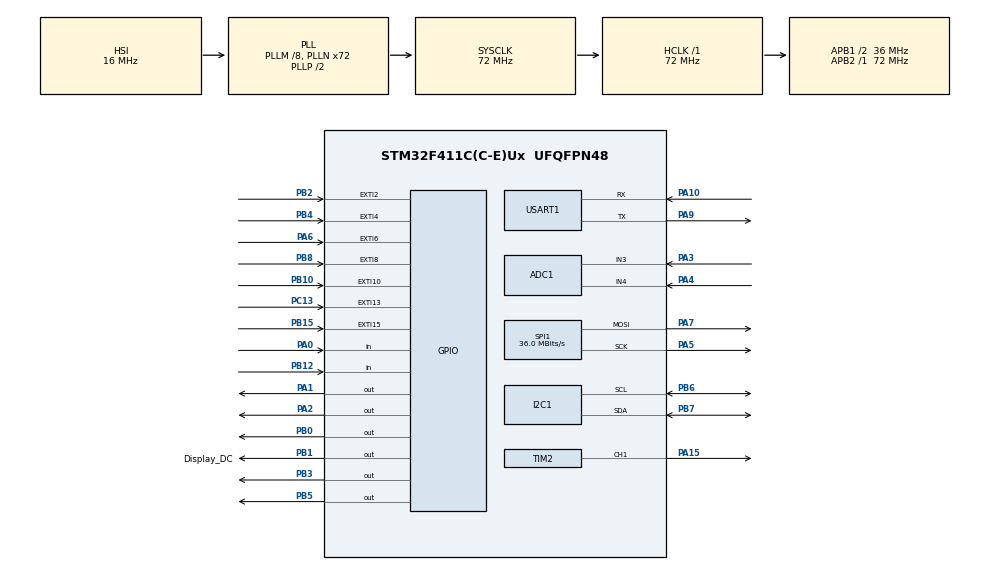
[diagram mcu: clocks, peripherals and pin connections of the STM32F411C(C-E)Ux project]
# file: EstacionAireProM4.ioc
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ADC1.Channel-0\#ChannelRegularConversion=ADC_CHANNEL_3
ADC1.ClockPrescaler=ADC_CLOCK_SYNC_PCLK_DIV4
ADC1.ContinuousConvMode=ENABLE
ADC1.NbrOfConversion=1
ADC1.NbrOfConversionFlag=1
ADC1.Rank-0\#ChannelRegularConversion=1
ADC1.SamplingTime-0\#ChannelRegularConversion=ADC_SAMPLETIME_3CYCLES
ADC1.master=1
Mcu.Family=STM32F4
Mcu.Name=STM32F411C(C-E)Ux
Mcu.Package=UFQFPN48
NVIC.EXTI15_10_IRQn=true\:0\:0\:false\:false\:true\:true\:true\:true
NVIC.EXTI2_IRQn=true\:0\:0\:false\:false\:true\:true\:true\:true
NVIC.EXTI4_IRQn=true\:0\:0\:false\:false\:true\:true\:true\:true
NVIC.EXTI9_5_IRQn=true\:0\:0\:false\:false\:true\:true\:true\:true
NVIC.PriorityGroup=NVIC_PRIORITYGROUP_4
NVIC.RCC_IRQn=true\:0\:0\:false\:false\:true\:true\:false\:true
NVIC.TIM2_IRQn=true\:0\:0\:false\:false\:true\:true\:true\:true
NVIC.TIM3_IRQn=true\:0\:0\:false\:false\:true\:true\:true\:true
PA0-WKUP.GPIO_PuPd=GPIO_PULLUP
PA0-WKUP.Signal=GPIO_Input
PA1.GPIO_ModeDefaultOutputPP=GPIO_MODE_OUTPUT_PP
PA1.Signal=GPIO_Output
PA10.Mode=Asynchronous
PA10.Signal=USART1_RX
PA13.Mode=Serial_Wire
PA13.Signal=SYS_JTMS-SWDIO
PA14.Mode=Serial_Wire
PA14.Signal=SYS_JTCK-SWCLK
PA15.GPIO_PuPd=GPIO_PULLUP
PA15.Signal=S_TIM2_CH1_ETR
PA2.Signal=GPIO_Output
PA3.Signal=ADCx_IN3
PA4.Signal=ADCx_IN4
PA5.Mode=TX_Only_Simplex_Unidirect_Master
PA5.Signal=SPI1_SCK
PA6.GPIO_ModeDefaultEXTI=GPIO_MODE_IT_RISING_FALLING
PA6.GPIO_PuPd=GPIO_PULLUP
PA6.Signal=GPXTI6
PA7.Mode=TX_Only_Simplex_Unidirect_Master
PA7.Signal=SPI1_MOSI
PA9.Mode=Asynchronous
PA9.Signal=USART1_TX
PB0.GPIO_PuPd=GPIO_PULLUP
PB0.Signal=GPIO_Output
PB1.GPIO_Label=Display_DC
PB1.GPIO_PuPd=GPIO_PULLUP
PB1.Signal=GPIO_Output
PB10.GPIO_ModeDefaultEXTI=GPIO_MODE_IT_RISING_FALLING
PB10.GPIO_PuPd=GPIO_PULLUP
PB10.Signal=GPXTI10
PB12.GPIO_PuPd=GPIO_PULLUP
PB12.Signal=GPIO_Input
PB15.GPIO_PuPd=GPIO_PULLUP
PB15.Signal=GPXTI15
PB2.GPIO_ModeDefaultEXTI=GPIO_MODE_IT_RISING_FALLING
PB2.GPIO_PuPd=GPIO_PULLUP
PB2.Signal=GPXTI2
PB3.PinState=GPIO_PIN_SET
PB3.Signal=GPIO_Output
PB4.Signal=GPXTI4
PB5.Signal=GPIO_Output
PB6.GPIO_Pu=GPIO_PULLUP
PB6.Mode=I2C
PB6.Signal=I2C1_SCL
PB7.GPIO_Pu=GPIO_PULLUP
PB7.Mode=I2C
PB7.Signal=I2C1_SDA
PB8.GPIO_PuPd=GPIO_PULLUP
PB8.Signal=GPXTI8
PC13-ANTI_TAMP.GPIO_ModeDefaultEXTI=GPIO_MODE_IT_RISING_FALLING
PC13-ANTI_TAMP.GPIO_PuPd=GPIO_PULLUP
PC13-ANTI_TAMP.Signal=GPXTI13
PH0\ -\ OSC_IN.Mode=HSE-External-Oscillator
PH0\ -\ OSC_IN.Signal=RCC_OSC_IN
PH1\ -\ OSC_OUT.Mode=HSE-External-Oscillator
PH1\ -\ OSC_OUT.Signal=RCC_OSC_OUT
ProjectManager.HeapSize=0x200
ProjectManager.StackSize=0x400
ProjectManager.TargetToolchain=STM32CubeIDE
RCC.48MHZClocksFreq_Value=36000000
RCC.AHBFreq_Value=72000000
RCC.APB1CLKDivider=RCC_HCLK_DIV2
RCC.APB1Freq_Value=36000000
RCC.APB1TimFreq_Value=72000000
RCC.APB2Freq_Value=72000000
RCC.APB2TimFreq_Value=72000000
RCC.CortexFreq_Value=72000000
RCC.HCLKFreq_Value=72000000
RCC.HSE_VALUE=25000000
RCC.HSI_VALUE=16000000
RCC.LSE_VALUE=32768
RCC.PLLM=8
RCC.PLLN=72
RCC.SYSCLKFreq_VALUE=72000000
RCC.SYSCLKSource=RCC_SYSCLKSOURCE_PLLCLK
RCC.VCOOutputFreq_Value=144000000
SH.ADCx_IN3.0=ADC1_IN3,IN3
SH.ADCx_IN4.0=ADC1_IN4,IN4
SH.S_TIM2_CH1_ETR.0=TIM2_CH1,PWM Generation1 CH1
SPI1.CalculateBaudRate=36.0 MBits/s
SPI1.Direction=SPI_DIRECTION_2LINES
SPI1.Mode=SPI_MODE_MASTER
SPI1.VirtualType=VM_MASTER
TIM2.AutoReloadPreload=TIM_AUTORELOAD_PRELOAD_ENABLE
TIM2.Channel-PWM\ Generation1\ CH1=TIM_CHANNEL_1
TIM2.Period=99
TIM2.Prescaler=71
USART1.VirtualMode=VM_ASYNC
VP_TIM2_VS_ClockSourceINT.Mode=Internal
VP_TIM3_VS_ClockSourceINT.Mode=Internal
board=custom

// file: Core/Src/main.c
/* USER CODE BEGIN Header */
/**
  ******************************************************************************
  * @file           : main.c
  * @brief          : Main program body
  ******************************************************************************
  * @attention
  *
  * Copyright (c) 2024 STMicroelectronics.
  * All rights reserved.
  *
  * This software is licensed under terms that can be found in the LICENSE file
  * in the root directory of this software component.
  * If no LICENSE file comes with this software, it is provided AS-IS.
  *
  ******************************************************************************
  */
/* USER CODE END Header */
#include "main.h"

ADC_HandleTypeDef hadc1;

I2C_HandleTypeDef hi2c1;

SPI_HandleTypeDef hspi1;

TIM_HandleTypeDef htim2;
TIM_HandleTypeDef htim3;

UART_HandleTypeDef huart1;

void SystemClock_Config(void);
static void MX_GPIO_Init(void);
static void MX_ADC1_Init(void);
static void MX_I2C1_Init(void);
static void MX_SPI1_Init(void);
static void MX_TIM2_Init(void);
static void MX_TIM3_Init(void);
static void MX_USART1_UART_Init(void);

int main(void)
{

  /* MCU Configuration--------------------------------------------------------*/

  /* Reset of all peripherals, Initializes the Flash interface and the Systick. */
  HAL_Init();

  /* Configure the system clock */
  SystemClock_Config();

  /* Initialize all configured peripherals */
  MX_GPIO_Init();
  MX_ADC1_Init();
  MX_I2C1_Init();
  MX_SPI1_Init();
  MX_TIM2_Init();
  MX_TIM3_Init();
  MX_USART1_UART_Init();
  /* USER CODE BEGIN 2 */
  HAL_TIM_Base_Start_IT(&htim3);
	IncializaSistema();
	EjecutaSistema();
  USART1_UART_Init();
	  HAL_ADC_Start(&hadc1);

  /* USER CODE END 2 */

  /* Infinite loop */
  /* USER CODE BEGIN WHILE */
  while (1)
  {
		int valor=HAL_ADC_GetValue(&hadc1);
		SerialPrintf((char*)"\r\n analogo: %d",valor);
		HAL_Delay(500);
    /* USER CODE END WHILE */

  }
}

void SystemClock_Config(void)
{
  RCC_OscInitTypeDef RCC_OscInitStruct = {0};
  RCC_ClkInitTypeDef RCC_ClkInitStruct = {0};

  /** Configure the main internal regulator output voltage
  */
  __HAL_RCC_PWR_CLK_ENABLE();
  __HAL_PWR_VOLTAGESCALING_CONFIG(PWR_REGULATOR_VOLTAGE_SCALE1);

  /** Initializes the RCC Oscillators according to the specified parameters
  * in the RCC_OscInitTypeDef structure.
  */
  RCC_OscInitStruct.OscillatorType = RCC_OSCILLATORTYPE_HSI;
  RCC_OscInitStruct.HSIState = RCC_HSI_ON;
  RCC_OscInitStruct.HSICalibrationValue = RCC_HSICALIBRATION_DEFAULT;
  RCC_OscInitStruct.PLL.PLLState = RCC_PLL_ON;
  RCC_OscInitStruct.PLL.PLLSource = RCC_PLLSOURCE_HSI;
  RCC_OscInitStruct.PLL.PLLM = 8;
  RCC_OscInitStruct.PLL.PLLN = 72;
  RCC_OscInitStruct.PLL.PLLP = RCC_PLLP_DIV2;
  RCC_OscInitStruct.PLL.PLLQ = 4;
  if (HAL_RCC_OscConfig(&RCC_OscInitStruct) != HAL_OK)
  {
    Error_Handler();
  }

  /** Initializes the CPU, AHB and APB buses clocks
  */
  RCC_ClkInitStruct.ClockType = RCC_CLOCKTYPE_HCLK|RCC_CLOCKTYPE_SYSCLK
                              |RCC_CLOCKTYPE_PCLK1|RCC_CLOCKTYPE_PCLK2;
  RCC_ClkInitStruct.SYSCLKSource = RCC_SYSCLKSOURCE_PLLCLK;
  RCC_ClkInitStruct.AHBCLKDivider = RCC_SYSCLK_DIV1;
  RCC_ClkInitStruct.APB1CLKDivider = RCC_HCLK_DIV2;
  RCC_ClkInitStruct.APB2CLKDivider = RCC_HCLK_DIV1;

  if (HAL_RCC_ClockConfig(&RCC_ClkInitStruct, FLASH_LATENCY_2) != HAL_OK)
  {
    Error_Handler();
  }
}

static void MX_ADC1_Init(void)
{

  ADC_ChannelConfTypeDef sConfig = {0};

  /** Configure the global features of the ADC (Clock, Resolution, Data Alignment and number of conversion)
  */
  hadc1.Instance = ADC1;
  hadc1.Init.ClockPrescaler = ADC_CLOCK_SYNC_PCLK_DIV4;
  hadc1.Init.Resolution = ADC_RESOLUTION_12B;
  hadc1.Init.ScanConvMode = DISABLE;
  hadc1.Init.ContinuousConvMode = ENABLE;
  hadc1.Init.DiscontinuousConvMode = DISABLE;
  hadc1.Init.ExternalTrigConvEdge = ADC_EXTERNALTRIGCONVEDGE_NONE;
  hadc1.Init.ExternalTrigConv = ADC_SOFTWARE_START;
  hadc1.Init.DataAlign = ADC_DATAALIGN_RIGHT;
  hadc1.Init.NbrOfConversion = 1;
  hadc1.Init.DMAContinuousRequests = DISABLE;
  hadc1.Init.EOCSelection = ADC_EOC_SINGLE_CONV;
  if (HAL_ADC_Init(&hadc1) != HAL_OK)
  {
    Error_Handler();
  }

  /** Configure for the selected ADC regular channel its corresponding rank in the sequencer and its sample time.
  */
  sConfig.Channel = ADC_CHANNEL_3;
  sConfig.Rank = 1;
  sConfig.SamplingTime = ADC_SAMPLETIME_3CYCLES;
  if (HAL_ADC_ConfigChannel(&hadc1, &sConfig) != HAL_OK)
  {
    Error_Handler();
  }

}

static void MX_I2C1_Init(void)
{

  hi2c1.Instance = I2C1;
  hi2c1.Init.ClockSpeed = 100000;
  hi2c1.Init.DutyCycle = I2C_DUTYCYCLE_2;
  hi2c1.Init.OwnAddress1 = 0;
  hi2c1.Init.AddressingMode = I2C_ADDRESSINGMODE_7BIT;
  hi2c1.Init.DualAddressMode = I2C_DUALADDRESS_DISABLE;
  hi2c1.Init.OwnAddress2 = 0;
  hi2c1.Init.GeneralCallMode = I2C_GENERALCALL_DISABLE;
  hi2c1.Init.NoStretchMode = I2C_NOSTRETCH_DISABLE;
  if (HAL_I2C_Init(&hi2c1) != HAL_OK)
  {
    Error_Handler();
  }

}

static void MX_SPI1_Init(void)
{

  /* SPI1 parameter configuration*/
  hspi1.Instance = SPI1;
  hspi1.Init.Mode = SPI_MODE_MASTER;
  hspi1.Init.Direction = SPI_DIRECTION_2LINES;
  hspi1.Init.DataSize = SPI_DATASIZE_8BIT;
  hspi1.Init.CLKPolarity = SPI_POLARITY_LOW;
  hspi1.Init.CLKPhase = SPI_PHASE_1EDGE;
  hspi1.Init.NSS = SPI_NSS_SOFT;
  hspi1.Init.BaudRatePrescaler = SPI_BAUDRATEPRESCALER_2;
  hspi1.Init.FirstBit = SPI_FIRSTBIT_MSB;
  hspi1.Init.TIMode = SPI_TIMODE_DISABLE;
  hspi1.Init.CRCCalculation = SPI_CRCCALCULATION_DISABLE;
  hspi1.Init.CRCPolynomial = 10;
  if (HAL_SPI_Init(&hspi1) != HAL_OK)
  {
    Error_Handler();
  }

}

static void MX_TIM2_Init(void)
{

  TIM_ClockConfigTypeDef sClockSourceConfig = {0};
  TIM_MasterConfigTypeDef sMasterConfig = {0};
  TIM_OC_InitTypeDef sConfigOC = {0};

  htim2.Instance = TIM2;
  htim2.Init.Prescaler = 71;
  htim2.Init.CounterMode = TIM_COUNTERMODE_UP;
  htim2.Init.Period = 99;
  htim2.Init.ClockDivision = TIM_CLOCKDIVISION_DIV1;
  htim2.Init.AutoReloadPreload = TIM_AUTORELOAD_PRELOAD_ENABLE;
  if (HAL_TIM_Base_Init(&htim2) != HAL_OK)
  {
    Error_Handler();
  }
  sClockSourceConfig.ClockSource = TIM_CLOCKSOURCE_INTERNAL;
  if (HAL_TIM_ConfigClockSource(&htim2, &sClockSourceConfig) != HAL_OK)
  {
    Error_Handler();
  }
  if (HAL_TIM_PWM_Init(&htim2) != HAL_OK)
  {
    Error_Handler();
  }
  sMasterConfig.MasterOutputTrigger = TIM_TRGO_RESET;
  sMasterConfig.MasterSlaveMode = TIM_MASTERSLAVEMODE_DISABLE;
  if (HAL_TIMEx_MasterConfigSynchronization(&htim2, &sMasterConfig) != HAL_OK)
  {
    Error_Handler();
  }
  sConfigOC.OCMode = TIM_OCMODE_PWM1;
  sConfigOC.Pulse = 0;
  sConfigOC.OCPolarity = TIM_OCPOLARITY_HIGH;
  sConfigOC.OCFastMode = TIM_OCFAST_DISABLE;
  if (HAL_TIM_PWM_ConfigChannel(&htim2, &sConfigOC, TIM_CHANNEL_1) != HAL_OK)
  {
    Error_Handler();
  }
  HAL_TIM_MspPostInit(&htim2);

}

static void MX_TIM3_Init(void)
{

  TIM_ClockConfigTypeDef sClockSourceConfig = {0};
  TIM_MasterConfigTypeDef sMasterConfig = {0};

  htim3.Instance = TIM3;
  htim3.Init.Prescaler = 0;
  htim3.Init.CounterMode = TIM_COUNTERMODE_UP;
  htim3.Init.Period = 65535;
  htim3.Init.ClockDivision = TIM_CLOCKDIVISION_DIV1;
  htim3.Init.AutoReloadPreload = TIM_AUTORELOAD_PRELOAD_DISABLE;
  if (HAL_TIM_Base_Init(&htim3) != HAL_OK)
  {
    Error_Handler();
  }
  sClockSourceConfig.ClockSource = TIM_CLOCKSOURCE_INTERNAL;
  if (HAL_TIM_ConfigClockSource(&htim3, &sClockSourceConfig) != HAL_OK)
  {
    Error_Handler();
  }
  sMasterConfig.MasterOutputTrigger = TIM_TRGO_RESET;
  sMasterConfig.MasterSlaveMode = TIM_MASTERSLAVEMODE_DISABLE;
  if (HAL_TIMEx_MasterConfigSynchronization(&htim3, &sMasterConfig) != HAL_OK)
  {
    Error_Handler();
  }

}

static void MX_USART1_UART_Init(void)
{

  huart1.Instance = USART1;
  huart1.Init.BaudRate = 115200;
  huart1.Init.WordLength = UART_WORDLENGTH_8B;
  huart1.Init.StopBits = UART_STOPBITS_1;
  huart1.Init.Parity = UART_PARITY_NONE;
  huart1.Init.Mode = UART_MODE_TX_RX;
  huart1.Init.HwFlowCtl = UART_HWCONTROL_NONE;
  huart1.Init.OverSampling = UART_OVERSAMPLING_16;
  if (HAL_UART_Init(&huart1) != HAL_OK)
  {
    Error_Handler();
  }

}

static void MX_GPIO_Init(void)
{
  GPIO_InitTypeDef GPIO_InitStruct = {0};

  /* GPIO Ports Clock Enable */
  __HAL_RCC_GPIOC_CLK_ENABLE();
  __HAL_RCC_GPIOH_CLK_ENABLE();
  __HAL_RCC_GPIOA_CLK_ENABLE();
  __HAL_RCC_GPIOB_CLK_ENABLE();

  /*Configure GPIO pin Output Level */
  HAL_GPIO_WritePin(GPIOA, GPIO_PIN_1|GPIO_PIN_2, GPIO_PIN_RESET);

  /*Configure GPIO pin Output Level */
  HAL_GPIO_WritePin(GPIOB, GPIO_PIN_0|Display_DC_Pin|GPIO_PIN_5, GPIO_PIN_RESET);

  /*Configure GPIO pin Output Level */
  HAL_GPIO_WritePin(GPIOB, GPIO_PIN_3, GPIO_PIN_SET);

  /*Configure GPIO pin : PC13 */
  GPIO_InitStruct.Pin = GPIO_PIN_13;
  GPIO_InitStruct.Mode = GPIO_MODE_IT_RISING_FALLING;
  GPIO_InitStruct.Pull = GPIO_PULLUP;
  HAL_GPIO_Init(GPIOC, &GPIO_InitStruct);

  /*Configure GPIO pin : PA0 */
  GPIO_InitStruct.Pin = GPIO_PIN_0;
  GPIO_InitStruct.Mode = GPIO_MODE_INPUT;
  GPIO_InitStruct.Pull = GPIO_PULLUP;
  HAL_GPIO_Init(GPIOA, &GPIO_InitStruct);

  /*Configure GPIO pins : PA1 PA2 */
  GPIO_InitStruct.Pin = GPIO_PIN_1|GPIO_PIN_2;
  GPIO_InitStruct.Mode = GPIO_MODE_OUTPUT_PP;
  GPIO_InitStruct.Pull = GPIO_NOPULL;
  GPIO_InitStruct.Speed = GPIO_SPEED_FREQ_LOW;
  HAL_GPIO_Init(GPIOA, &GPIO_InitStruct);

  /*Configure GPIO pin : PA6 */
  GPIO_InitStruct.Pin = GPIO_PIN_6;
  GPIO_InitStruct.Mode = GPIO_MODE_IT_RISING_FALLING;
  GPIO_InitStruct.Pull = GPIO_PULLUP;
  HAL_GPIO_Init(GPIOA, &GPIO_InitStruct);

  /*Configure GPIO pins : PB0 Display_DC_Pin */
  GPIO_InitStruct.Pin = GPIO_PIN_0|Display_DC_Pin;
  GPIO_InitStruct.Mode = GPIO_MODE_OUTPUT_PP;
  GPIO_InitStruct.Pull = GPIO_PULLUP;
  GPIO_InitStruct.Speed = GPIO_SPEED_FREQ_LOW;
  HAL_GPIO_Init(GPIOB, &GPIO_InitStruct);

  /*Configure GPIO pins : PB2 PB10 */
  GPIO_InitStruct.Pin = GPIO_PIN_2|GPIO_PIN_10;
  GPIO_InitStruct.Mode = GPIO_MODE_IT_RISING_FALLING;
  GPIO_InitStruct.Pull = GPIO_PULLUP;
  HAL_GPIO_Init(GPIOB, &GPIO_InitStruct);

  /*Configure GPIO pin : PB12 */
  GPIO_InitStruct.Pin = GPIO_PIN_12;
  GPIO_InitStruct.Mode = GPIO_MODE_INPUT;
  GPIO_InitStruct.Pull = GPIO_PULLUP;
  HAL_GPIO_Init(GPIOB, &GPIO_InitStruct);

  /*Configure GPIO pins : PB15 PB8 */
  GPIO_InitStruct.Pin = GPIO_PIN_15|GPIO_PIN_8;
  GPIO_InitStruct.Mode = GPIO_MODE_IT_RISING;
  GPIO_InitStruct.Pull = GPIO_PULLUP;
  HAL_GPIO_Init(GPIOB, &GPIO_InitStruct);

  /*Configure GPIO pins : PB3 PB5 */
  GPIO_InitStruct.Pin = GPIO_PIN_3|GPIO_PIN_5;
  GPIO_InitStruct.Mode = GPIO_MODE_OUTPUT_PP;
  GPIO_InitStruct.Pull = GPIO_NOPULL;
  GPIO_InitStruct.Speed = GPIO_SPEED_FREQ_LOW;
  HAL_GPIO_Init(GPIOB, &GPIO_InitStruct);

  /*Configure GPIO pin : PB4 */
  GPIO_InitStruct.Pin = GPIO_PIN_4;
  GPIO_InitStruct.Mode = GPIO_MODE_IT_RISING;
  GPIO_InitStruct.Pull = GPIO_NOPULL;
  HAL_GPIO_Init(GPIOB, &GPIO_InitStruct);

  /* EXTI interrupt init*/
  HAL_NVIC_SetPriority(EXTI2_IRQn, 0, 0);
  HAL_NVIC_EnableIRQ(EXTI2_IRQn);

  HAL_NVIC_SetPriority(EXTI4_IRQn, 0, 0);
  HAL_NVIC_EnableIRQ(EXTI4_IRQn);

  HAL_NVIC_SetPriority(EXTI9_5_IRQn, 0, 0);
  HAL_NVIC_EnableIRQ(EXTI9_5_IRQn);

  HAL_NVIC_SetPriority(EXTI15_10_IRQn, 0, 0);
  HAL_NVIC_EnableIRQ(EXTI15_10_IRQn);

}

void Error_Handler(void)
{
  __disable_irq();
  while (1)
  {
  }
}
